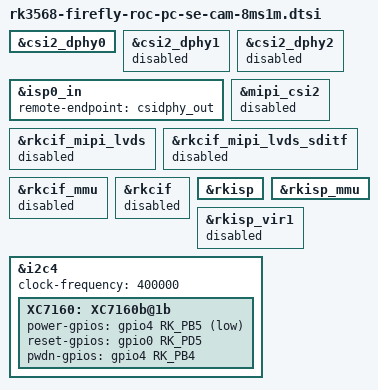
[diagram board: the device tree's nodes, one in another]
// SPDX-License-Identifier: (GPL-2.0+ OR MIT)
/*
 * Copyright (c) 2020 Rockchip Electronics Co., Ltd.
 *
 */

/* 8M  single camera xc7160sc8238*/

/*
* csi2_dphy0: used for csi2 dphy full mode,
        is mutually exclusive with
        csi2_dphy1 and csi2_dphy2
* csi2_dphy1: used for csi2 dphy split mode,
        physical lanes use lane0 and lane1,
        can be used with csi2_dphy2  parallel
* csi2_dphy2: used for csi2 dphy split mode,
        physical lanes use lane2 and lane3,
        can be used with csi2_dphy1  parallel
*/

&csi2_dphy0 {
        status = "okay";
};

&csi2_dphy1 {
	status = "disabled";
};

&csi2_dphy2 {
	status = "disabled";
};

/*
 * csidphy_out ----> csi2_dphy0
 * dphy1_out   ----> csi2_dphy1
 * dphy2_out   ----> csi2_dphy2
 */
&isp0_in {
     remote-endpoint = <&csidphy_out>;
};

&mipi_csi2 {
    status = "disabled";
};

&rkcif_mipi_lvds {
    status = "disabled";
};

&rkcif_mipi_lvds_sditf {
	status = "disabled";
};

&rkcif_mmu {
    status = "disabled";
};

&rkcif {
    status = "disabled";
};

&rkisp {
	status = "okay";
};

&rkisp_mmu {
	status = "okay";
};


&mipi_csi2 {
    status = "disabled";
};

&rkisp_vir1 {
    status = "disabled";
};



&i2c4 {
	status = "okay";
    clock-frequency = <400000>;

    XC7160: XC7160b@1b{
        status = "okay";
        power-gpios = <&gpio4 RK_PB5 GPIO_ACTIVE_LOW>;
        reset-gpios = <&gpio0 RK_PD5 GPIO_ACTIVE_HIGH>;
        pwdn-gpios = <&gpio4 RK_PB4 GPIO_ACTIVE_HIGH>;
	};

};

